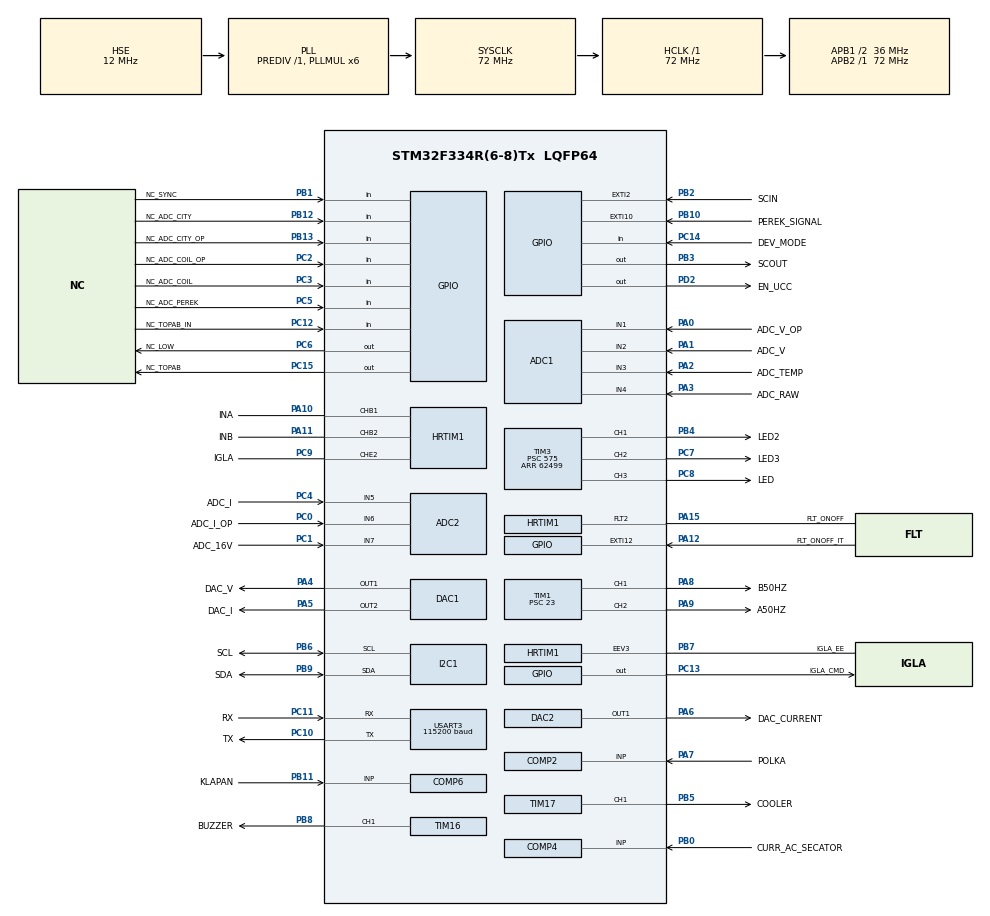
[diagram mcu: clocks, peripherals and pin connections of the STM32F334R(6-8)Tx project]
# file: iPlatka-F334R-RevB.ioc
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ADC1.AWD1HighThreshold=4095
ADC1.AWD1ITMode=ENABLE
ADC1.AWD1LowThreshold=1000
ADC1.AWD2HighThreshold=2000
ADC1.AWD2ITMode=ENABLE
ADC1.AWD2LowThreshold=1000
ADC1.AWD3HighThreshold=3000
ADC1.AWD3ITMode=ENABLE
ADC1.AWD3LowThreshold=2001
ADC1.AWDChannel-0\#ChannelRegularConversion=ADC_CHANNEL_3
ADC1.AWDChannel-6\#ChannelRegularConversion=ADC_CHANNEL_4
ADC1.Channel-0\#ChannelRegularConversion=ADC_CHANNEL_3
ADC1.Channel-6\#ChannelRegularConversion=ADC_CHANNEL_4
ADC1.ContinuousConvMode=ENABLE
ADC1.DMAContinuousRequests=ENABLE
ADC1.EOCSelection=ADC_EOC_SEQ_CONV
ADC1.EnableAnalogWatchDog1=true
ADC1.EnableAnalogWatchDog2=true
ADC1.EnableAnalogWatchDog3=true
ADC1.ExternalTrigInjecConv=ADC_EXTERNALTRIGINJECCONV_HRTIM_TRG2
ADC1.ExternalTrigInjecConvEdge=ADC_EXTERNALTRIGINJECCONV_EDGE_RISING
ADC1.InjNumberOfConversion=2
ADC1.InjectedChannel-1\#ChannelInjectedConversion=ADC_CHANNEL_2
ADC1.InjectedChannel-5\#ChannelInjectedConversion=ADC_CHANNEL_1
ADC1.InjectedOffset-1\#ChannelInjectedConversion=0
ADC1.InjectedOffset-5\#ChannelInjectedConversion=0
ADC1.InjectedOffsetNumber-1\#ChannelInjectedConversion=ADC_OFFSET_NONE
ADC1.InjectedOffsetNumber-5\#ChannelInjectedConversion=ADC_OFFSET_NONE
ADC1.InjectedRank-1\#ChannelInjectedConversion=1
ADC1.InjectedRank-5\#ChannelInjectedConversion=2
ADC1.InjectedSamplingTime-1\#ChannelInjectedConversion=ADC_SAMPLETIME_19CYCLES_5
ADC1.InjectedSamplingTime-5\#ChannelInjectedConversion=ADC_SAMPLETIME_19CYCLES_5
ADC1.MonitoredBy-0\#ChannelRegularConversion=ADC_ANALOGWATCHDOG_3
ADC1.MonitoredBy-6\#ChannelRegularConversion=ADC_ANALOGWATCHDOG_2
ADC1.NbrOfConversion=2
ADC1.NbrOfConversionFlag=1
ADC1.Offset-0\#ChannelRegularConversion=0
ADC1.Offset-6\#ChannelRegularConversion=0
ADC1.OffsetNumber-0\#ChannelRegularConversion=ADC_OFFSET_NONE
ADC1.OffsetNumber-6\#ChannelRegularConversion=ADC_OFFSET_NONE
ADC1.Rank-0\#ChannelRegularConversion=1
ADC1.Rank-6\#ChannelRegularConversion=2
ADC1.SamplingTime-0\#ChannelRegularConversion=ADC_SAMPLETIME_601CYCLES_5
ADC1.SamplingTime-6\#ChannelRegularConversion=ADC_SAMPLETIME_601CYCLES_5
ADC1.SubFamily=STM32F334x8
ADC1.WatchdogChannel=ADC_CHANNEL_4
ADC1.master=1
ADC2.AWD1HighThreshold=3000
ADC2.AWD1ITMode=ENABLE
ADC2.AWD1LowThreshold=1000
ADC2.AWD2HighThreshold=4000
ADC2.AWD2ITMode=ENABLE
ADC2.AWD2LowThreshold=1000
ADC2.AWD3HighThreshold=3000
ADC2.AWD3ITMode=ENABLE
ADC2.AWD3LowThreshold=1000
ADC2.AWDChannel-0\#ChannelRegularConversion=ADC_CHANNEL_7
ADC2.Channel-0\#ChannelRegularConversion=ADC_CHANNEL_7
ADC2.ContinuousConvMode=ENABLE
ADC2.DMAContinuousRequests=ENABLE
ADC2.EOCSelection=ADC_EOC_SEQ_CONV
ADC2.EnableAnalogWatchDog1=true
ADC2.EnableAnalogWatchDog2=true
ADC2.EnableAnalogWatchDog3=true
ADC2.ExternalTrigInjecConv=ADC_EXTERNALTRIGINJECCONV_HRTIM_TRG2
ADC2.InjAWDChannel-2\#ChannelInjectedConversion=ADC_CHANNEL_6
ADC2.InjMonitoredBy-2\#ChannelInjectedConversion=ADC_ANALOGWATCHDOG_2
ADC2.InjNumberOfConversion=2
ADC2.InjectedChannel-1\#ChannelInjectedConversion=ADC_CHANNEL_5
ADC2.InjectedChannel-2\#ChannelInjectedConversion=ADC_CHANNEL_6
ADC2.InjectedOffset-1\#ChannelInjectedConversion=0
ADC2.InjectedOffset-2\#ChannelInjectedConversion=0
ADC2.InjectedOffsetNumber-1\#ChannelInjectedConversion=ADC_OFFSET_NONE
ADC2.InjectedOffsetNumber-2\#ChannelInjectedConversion=ADC_OFFSET_NONE
ADC2.InjectedRank-1\#ChannelInjectedConversion=1
ADC2.InjectedRank-2\#ChannelInjectedConversion=2
ADC2.InjectedSamplingTime-1\#ChannelInjectedConversion=ADC_SAMPLETIME_19CYCLES_5
ADC2.InjectedSamplingTime-2\#ChannelInjectedConversion=ADC_SAMPLETIME_19CYCLES_5
ADC2.MonitoredBy-0\#ChannelRegularConversion=ADC_ANALOGWATCHDOG_3
ADC2.NbrOfConversionFlag=1
ADC2.Offset-0\#ChannelRegularConversion=0
ADC2.OffsetNumber-0\#ChannelRegularConversion=ADC_OFFSET_NONE
ADC2.Rank-0\#ChannelRegularConversion=1
ADC2.SamplingTime-0\#ChannelRegularConversion=ADC_SAMPLETIME_601CYCLES_5
ADC2.SubFamily=STM32F334x8
ADC2.WatchdogChannel=ADC_CHANNEL_7
COMP2.InvertingInput=COMP_INVERTINGINPUT_DAC1_CH2
COMP2.TriggerMode=COMP_TRIGGERMODE_NONE
COMP4.InvertingInput=COMP_INVERTINGINPUT_DAC2_CH1
COMP4.TriggerMode=COMP_TRIGGERMODE_NONE
COMP6.InvertingInput=COMP_INVERTINGINPUT_DAC1_CH2
COMP6.TriggerMode=COMP_TRIGGERMODE_IT_RISING_FALLING
DAC1.DAC_Trigger=DAC_TRIGGER_HRTIM1_DACTRG1
DAC1.DAC_Trigger2=DAC_TRIGGER_HRTIM1_DACTRG1
DAC1.TriangleAmplitude=DAC_TRIANGLEAMPLITUDE_7
DAC1.TriangleAmplitude2=DAC_TRIANGLEAMPLITUDE_7
DAC1.WaveGeneration=TriangleWaveGeneration
DAC1.WaveGeneration2=TriangleWaveGeneration
DAC2.DAC_Trigger=DAC_TRIGGER_HRTIM1_DACTRG3
Dma.ADC1.3.Direction=DMA_PERIPH_TO_MEMORY
Dma.ADC1.3.Instance=DMA1_Channel1
Dma.ADC1.3.MemDataAlignment=DMA_MDATAALIGN_HALFWORD
Dma.ADC1.3.MemInc=DMA_MINC_ENABLE
Dma.ADC1.3.Mode=DMA_CIRCULAR
Dma.ADC1.3.PeriphDataAlignment=DMA_PDATAALIGN_HALFWORD
Dma.ADC1.3.PeriphInc=DMA_PINC_DISABLE
Dma.ADC1.3.Priority=DMA_PRIORITY_HIGH
Dma.ADC2.4.Direction=DMA_PERIPH_TO_MEMORY
Dma.ADC2.4.Instance=DMA1_Channel4
Dma.ADC2.4.MemDataAlignment=DMA_MDATAALIGN_HALFWORD
Dma.ADC2.4.MemInc=DMA_MINC_ENABLE
Dma.ADC2.4.Mode=DMA_CIRCULAR
Dma.ADC2.4.PeriphDataAlignment=DMA_PDATAALIGN_HALFWORD
Dma.ADC2.4.PeriphInc=DMA_PINC_DISABLE
Dma.ADC2.4.Priority=DMA_PRIORITY_HIGH
Dma.I2C1_RX.5.Direction=DMA_PERIPH_TO_MEMORY
Dma.I2C1_RX.5.Instance=DMA1_Channel5
Dma.I2C1_RX.5.MemDataAlignment=DMA_MDATAALIGN_BYTE
Dma.I2C1_RX.5.MemInc=DMA_MINC_ENABLE
Dma.I2C1_RX.5.Mode=DMA_CIRCULAR
Dma.I2C1_RX.5.PeriphDataAlignment=DMA_PDATAALIGN_BYTE
Dma.I2C1_RX.5.PeriphInc=DMA_PINC_DISABLE
Dma.I2C1_RX.5.Priority=DMA_PRIORITY_LOW
Dma.I2C1_TX.2.Direction=DMA_MEMORY_TO_PERIPH
Dma.I2C1_TX.2.Instance=DMA1_Channel6
Dma.I2C1_TX.2.MemDataAlignment=DMA_MDATAALIGN_BYTE
Dma.I2C1_TX.2.MemInc=DMA_MINC_ENABLE
Dma.I2C1_TX.2.Mode=DMA_CIRCULAR
Dma.I2C1_TX.2.PeriphDataAlignment=DMA_PDATAALIGN_BYTE
Dma.I2C1_TX.2.PeriphInc=DMA_PINC_DISABLE
Dma.I2C1_TX.2.Priority=DMA_PRIORITY_MEDIUM
Dma.Request0=USART3_TX
Dma.Request1=USART3_RX
Dma.Request2=I2C1_TX
Dma.Request3=ADC1
Dma.Request4=ADC2
Dma.Request5=I2C1_RX
Dma.USART3_RX.1.Direction=DMA_PERIPH_TO_MEMORY
Dma.USART3_RX.1.Instance=DMA1_Channel3
Dma.USART3_RX.1.MemDataAlignment=DMA_MDATAALIGN_BYTE
Dma.USART3_RX.1.MemInc=DMA_MINC_ENABLE
Dma.USART3_RX.1.Mode=DMA_CIRCULAR
Dma.USART3_RX.1.PeriphDataAlignment=DMA_PDATAALIGN_BYTE
Dma.USART3_RX.1.PeriphInc=DMA_PINC_DISABLE
Dma.USART3_RX.1.Priority=DMA_PRIORITY_LOW
Dma.USART3_TX.0.Direction=DMA_MEMORY_TO_PERIPH
Dma.USART3_TX.0.Instance=DMA1_Channel2
Dma.USART3_TX.0.MemDataAlignment=DMA_MDATAALIGN_BYTE
Dma.USART3_TX.0.MemInc=DMA_MINC_ENABLE
Dma.USART3_TX.0.Mode=DMA_CIRCULAR
Dma.USART3_TX.0.PeriphDataAlignment=DMA_PDATAALIGN_BYTE
Dma.USART3_TX.0.PeriphInc=DMA_PINC_DISABLE
Dma.USART3_TX.0.Priority=DMA_PRIORITY_MEDIUM
FREERTOS.Tasks01=BootOcIgla,24,128,StartBootOcIgla,Default,NULL,Dynamic,NULL,NULL;BuzzerCoolerLed,16,128,StartBuzzerCoolerLed_5Sec,Default,NULL,Dynamic,NULL,NULL;ADC_TEMP_V16_RA,16,128,StartADC_TEMP_V16_RAW,Default,NULL,Dynamic,NULL,NULL;UART_I2C,8,128,StartUART_I2C,Default,NULL,Dynamic,NULL,NULL
FREERTOS.configTOTAL_HEAP_SIZE=2600
HRTIM1.ADCTrigger2_Source1=HRTIM_ADCTRIGGEREVENT24_MASTER_CMP2
HRTIM1.ADCTrigger2_Source2=HRTIM_ADCTRIGGEREVENT24_MASTER_CMP4
HRTIM1.ADCTrigger_Id2=HRTIM_ADCTRIGGER_2
HRTIM1.CaptureUnit1-No_output_TA=HRTIM_CAPTUREUNIT_1
HRTIM1.CaptureUnit1-No_output_TC=HRTIM_CAPTUREUNIT_1
HRTIM1.CaptureUnit1-No_output_TD=HRTIM_CAPTUREUNIT_1
HRTIM1.CaptureUnit2-No_output_TA=HRTIM_CAPTUREUNIT_2
HRTIM1.CaptureUnit2-No_output_TC=HRTIM_CAPTUREUNIT_2
HRTIM1.CompareUnit1-MasterTimer=HRTIM_COMPAREUNIT_1
HRTIM1.CompareUnit1-No_output_TA=__NULL
HRTIM1.CompareUnit1-Output_TB1TB2=HRTIM_COMPAREUNIT_1
HRTIM1.CompareUnit2-MasterTimer=HRTIM_COMPAREUNIT_2
HRTIM1.CompareUnit2-Output_TB1TB2=HRTIM_COMPAREUNIT_2
HRTIM1.CompareUnit3-MasterTimer=HRTIM_COMPAREUNIT_3
HRTIM1.CompareUnit3-Output_TB1TB2=HRTIM_COMPAREUNIT_3
HRTIM1.CompareUnit4-MasterTimer=HRTIM_COMPAREUNIT_4
HRTIM1.CompareUnit4-Output_TB1TB2=HRTIM_COMPAREUNIT_4
HRTIM1.CompareValue1-MasterTimer=3456
HRTIM1.CompareValue1-Output_TB1TB2=3456
HRTIM1.CompareValue2-MasterTimer=5760
HRTIM1.CompareValue2-Output_TB1TB2=32000
HRTIM1.CompareValue3-MasterTimer=35456
HRTIM1.CompareValue3-Output_TB1TB2=35456
HRTIM1.CompareValue4-MasterTimer=37760
HRTIM1.CompareValue4-Output_TB1TB2=64000
HRTIM1.DACSynchro-No_output_TA=HRTIM_DACSYNC_DACTRIGOUT_1
HRTIM1.DACSynchro-No_output_TC=HRTIM_DACSYNC_DACTRIGOUT_3
HRTIM1.DACSynchro-Output_TB1TB2=HRTIM_DACSYNC_NONE
HRTIM1.DACSynchro-Output_TE2=HRTIM_DACSYNC_DACTRIGOUT_1
HRTIM1.Event_EEV1=HRTIM_EVENT_1
HRTIM1.Event_EEV2=HRTIM_EVENT_2
HRTIM1.Event_EEV4=HRTIM_EVENT_4
HRTIM1.Event_EEV5=HRTIM_EVENT_5
HRTIM1.Event_EEV6=HRTIM_EVENT_6
HRTIM1.Event_EEV7=HRTIM_EVENT_7
HRTIM1.Event_EEV8=HRTIM_EVENT_8
HRTIM1.Event_EEV9=__NULL
HRTIM1.FastMode_EEV1=HRTIM_EVENTFASTMODE_ENABLE
HRTIM1.FastMode_EEV2=HRTIM_EVENTFASTMODE_ENABLE
HRTIM1.FastMode_EEV3=HRTIM_EVENTFASTMODE_ENABLE
HRTIM1.FastMode_EEV5=HRTIM_EVENTFASTMODE_ENABLE
HRTIM1.FaultEnable_Source1-No_output_TA=HRTIM_TIMFAULTENABLE_FAULT2
HRTIM1.FaultEnable_Source1-No_output_TC=HRTIM_TIMFAULTENABLE_FAULT2
HRTIM1.FaultEnable_Source1-No_output_TD=HRTIM_TIMFAULTENABLE_FAULT2
HRTIM1.FaultEnable_Source1-Output_TB1TB2=HRTIM_TIMFAULTENABLE_FAULT2
HRTIM1.FaultEnable_Source1-Output_TE2=HRTIM_TIMFAULTENABLE_FAULT2
HRTIM1.FaultLevel1-Output_TB1TB2=HRTIM_OUTPUTFAULTLEVEL_INACTIVE
HRTIM1.FaultLevel2-Output_TB1TB2=HRTIM_OUTPUTFAULTLEVEL_INACTIVE
HRTIM1.FaultLevel2-Output_TE2=HRTIM_OUTPUTFAULTLEVEL_INACTIVE
HRTIM1.Filter_EEV6=HRTIM_EVENTFILTER_15
HRTIM1.Filter_EEV8=HRTIM_EVENTFILTER_15
HRTIM1.Filter_FaultLine2=HRTIM_FAULTFILTER_15
HRTIM1.HRTIMInterruptResquests1=HRTIM_IT_FLT2
HRTIM1.HRTIMInterruptResquests2=HRTIM_IT_SYSFLT
HRTIM1.InterruptRequests1-No_output_TA=HRTIM_TIM_IT_CPT1
HRTIM1.InterruptRequests1-No_output_TC=HRTIM_TIM_IT_CPT1
HRTIM1.InterruptRequests1-No_output_TD=HRTIM_TIM_IT_CPT1
HRTIM1.InterruptRequests1_Master=HRTIM_MASTER_IT_MREP
HRTIM1.InterruptRequests2-No_output_TA=HRTIM_TIM_IT_CPT2
HRTIM1.InterruptRequests2-No_output_TC=HRTIM_TIM_IT_CPT2
HRTIM1.ModeTimeBase-No_output_TA=HRTIM_MODE_SINGLESHOT_RETRIGGERABLE
HRTIM1.ModeTimeBase-No_output_TC=HRTIM_MODE_SINGLESHOT_RETRIGGERABLE
HRTIM1.ModeTimeBase-No_output_TD=HRTIM_MODE_SINGLESHOT_RETRIGGERABLE
HRTIM1.ModeTimeBase-Output_TB1TB2=HRTIM_MODE_SINGLESHOT
HRTIM1.ModeTimeBase-Output_TE2=HRTIM_MODE_SINGLESHOT_RETRIGGERABLE
HRTIM1.NumberADCTriggerSource2=2
HRTIM1.NumberFaultEnable-No_output_TA=1
HRTIM1.NumberFaultEnable-No_output_TC=1
HRTIM1.NumberFaultEnable-No_output_TD=1
HRTIM1.NumberFaultEnable-Output_TB1TB2=1
HRTIM1.NumberFaultEnable-Output_TE2=1
HRTIM1.NumberInterruptRequests-No_output_TA=2
HRTIM1.NumberInterruptRequests-No_output_TC=2
HRTIM1.NumberInterruptRequests-No_output_TD=1
HRTIM1.NumberInterruptRequests_Master-MasterTimer=1
HRTIM1.NumberResetSource1-Output_TB1TB2=15
HRTIM1.NumberResetSource2-Output_TE2=8
HRTIM1.NumberResetSource2_TB=15
HRTIM1.NumberResetTrigger-No_output_TA=1
HRTIM1.NumberResetTrigger-No_output_TC=1
HRTIM1.NumberResetTrigger-No_output_TD=1
HRTIM1.NumberResetTrigger-Output_TB1TB2=1
HRTIM1.NumberResetTrigger-Output_TE2=1
HRTIM1.NumberSetSource1-Output_TB1TB2=1
HRTIM1.NumberSetSource2-Output_TE2=1
HRTIM1.NumberSetSource2_TB=1
HRTIM1.NumberTriggerSource_Captureconfig1-No_output_TA=1
HRTIM1.NumberTriggerSource_Captureconfig1-No_output_TC=1
HRTIM1.NumberTriggerSource_Captureconfig1-No_output_TD=1
HRTIM1.NumberTriggerSource_Captureconfig2-No_output_TA=1
HRTIM1.NumberTriggerSource_Captureconfig2-No_output_TC=1
HRTIM1.NumberUpdateTrigger-No_output_TA=1
HRTIM1.NumberUpdateTrigger-No_output_TC=1
HRTIM1.NumberUpdateTrigger-No_output_TD=1
HRTIM1.NumberUpdateTrigger-Output_TB1TB2=1
HRTIM1.NumberUpdateTrigger-Output_TE2=1
HRTIM1.Periode_MASTER=64000
HRTIM1.Periode_TA=32000
HRTIM1.Periode_TB=64000
HRTIM1.Periode_TC=32000
HRTIM1.Periode_TD=64000
HRTIM1.Periode_TE=64000
HRTIM1.Polarity_FaultLine2=HRTIM_FAULTPOLARITY_LOW
HRTIM1.PreloadEnable-MasterTimer=HRTIM_PRELOAD_ENABLED
HRTIM1.PreloadEnable-Output_TE2=HRTIM_PRELOAD_DISABLED
HRTIM1.PrescalerRatio_MASTER=HRTIM_PRESCALERRATIO_MUL16
HRTIM1.PrescalerRatio_TA=HRTIM_PRESCALERRATIO_MUL16
HRTIM1.PrescalerRatio_TB=HRTIM_PRESCALERRATIO_MUL16
HRTIM1.PrescalerRatio_TC=HRTIM_PRESCALERRATIO_MUL16
HRTIM1.PrescalerRatio_TD=HRTIM_PRESCALERRATIO_MUL16
HRTIM1.PrescalerRatio_TE=HRTIM_PRESCALERRATIO_MUL16
HRTIM1.RepetitionCounter-MasterTimer=0
HRTIM1.RepetitionUpdate-MasterTimer=HRTIM_UPDATEONREPETITION_ENABLED
HRTIM1.RepetitionUpdate-No_output_TA=HRTIM_UPDATEONREPETITION_ENABLED
HRTIM1.RepetitionUpdate-No_output_TC=HRTIM_UPDATEONREPETITION_ENABLED
HRTIM1.RepetitionUpdate-No_output_TD=HRTIM_UPDATEONREPETITION_ENABLED
HRTIM1.RepetitionUpdate-Output_TB1TB2=HRTIM_UPDATEONREPETITION_ENABLED
HRTIM1.RepetitionUpdate-Output_TE2=HRTIM_UPDATEONREPETITION_ENABLED
HRTIM1.ResetOutput1_Source1-Output_TB1TB2=HRTIM_OUTPUTRESET_TIMCMP2
HRTIM1.ResetOutput1_Source10-Output_TB1TB2=HRTIM_OUTPUTRESET_EEV_4
HRTIM1.ResetOutput1_Source11-Output_TB1TB2=HRTIM_OUTPUTRESET_EEV_5
HRTIM1.ResetOutput1_Source12-Output_TB1TB2=HRTIM_OUTPUTRESET_EEV_6
HRTIM1.ResetOutput1_Source13-Output_TB1TB2=HRTIM_OUTPUTRESET_EEV_7
HRTIM1.ResetOutput1_Source14-Output_TB1TB2=HRTIM_OUTPUTRESET_EEV_8
HRTIM1.ResetOutput1_Source15-Output_TB1TB2=HRTIM_OUTPUTRESET_EEV_1
HRTIM1.ResetOutput1_Source2-Output_TB1TB2=HRTIM_OUTPUTRESET_TIMCMP3
HRTIM1.ResetOutput1_Source3-Output_TB1TB2=HRTIM_OUTPUTRESET_TIMCMP4
HRTIM1.ResetOutput1_Source4-Output_TB1TB2=HRTIM_OUTPUTRESET_TIMPER
HRTIM1.ResetOutput1_Source5-Output_TB1TB2=HRTIM_OUTPUTRESET_UPDATE
HRTIM1.ResetOutput1_Source6-Output_TB1TB2=HRTIM_OUTPUTRESET_MASTERPER
HRTIM1.ResetOutput1_Source7-Output_TB1TB2=HRTIM_OUTPUTRESET_MASTERCMP3
HRTIM1.ResetOutput1_Source8-Output_TB1TB2=HRTIM_OUTPUTRESET_MASTERCMP4
HRTIM1.ResetOutput1_Source9-Output_TB1TB2=HRTIM_OUTPUTRESET_EEV_2
HRTIM1.ResetOutput2_Source1-Output_TB1TB2=HRTIM_OUTPUTRESET_TIMCMP1
HRTIM1.ResetOutput2_Source1-Output_TE2=HRTIM_OUTPUTRESET_EEV_3
HRTIM1.ResetOutput2_Source10-Output_TB1TB2=HRTIM_OUTPUTRESET_EEV_4
HRTIM1.ResetOutput2_Source11-Output_TB1TB2=HRTIM_OUTPUTRESET_EEV_5
HRTIM1.ResetOutput2_Source12-Output_TB1TB2=HRTIM_OUTPUTRESET_EEV_6
HRTIM1.ResetOutput2_Source13-Output_TB1TB2=HRTIM_OUTPUTRESET_EEV_8
HRTIM1.ResetOutput2_Source14-Output_TB1TB2=HRTIM_OUTPUTRESET_EEV_7
HRTIM1.ResetOutput2_Source15-Output_TB1TB2=HRTIM_OUTPUTRESET_EEV_1
HRTIM1.ResetOutput2_Source2-Output_TB1TB2=HRTIM_OUTPUTRESET_TIMCMP2
HRTIM1.ResetOutput2_Source2-Output_TE2=HRTIM_OUTPUTRESET_EEV_4
HRTIM1.ResetOutput2_Source3-Output_TB1TB2=HRTIM_OUTPUTRESET_TIMCMP4
HRTIM1.ResetOutput2_Source3-Output_TE2=HRTIM_OUTPUTRESET_EEV_6
HRTIM1.ResetOutput2_Source4-Output_TB1TB2=HRTIM_OUTPUTRESET_UPDATE
HRTIM1.ResetOutput2_Source4-Output_TE2=HRTIM_OUTPUTRESET_EEV_5
HRTIM1.ResetOutput2_Source5-Output_TB1TB2=HRTIM_OUTPUTRESET_TIMPER
HRTIM1.ResetOutput2_Source5-Output_TE2=HRTIM_OUTPUTRESET_EEV_2
HRTIM1.ResetOutput2_Source6-Output_TB1TB2=HRTIM_OUTPUTRESET_MASTERCMP1
HRTIM1.ResetOutput2_Source6-Output_TE2=HRTIM_OUTPUTRESET_EEV_8
HRTIM1.ResetOutput2_Source7-Output_TB1TB2=HRTIM_OUTPUTRESET_MASTERCMP2
HRTIM1.ResetOutput2_Source7-Output_TE2=HRTIM_OUTPUTRESET_EEV_7
HRTIM1.ResetOutput2_Source8-Output_TB1TB2=HRTIM_OUTPUTRESET_MASTERPER
HRTIM1.ResetOutput2_Source8-Output_TE2=HRTIM_OUTPUTRESET_EEV_1
HRTIM1.ResetOutput2_Source9-Output_TB1TB2=HRTIM_OUTPUTRESET_EEV_2
HRTIM1.ResetTrigger1-No_output_TA=HRTIM_TIMRESETTRIGGER_MASTER_PER
HRTIM1.ResetTrigger1-No_output_TC=HRTIM_TIMRESETTRIGGER_OTHER2_CMP2
HRTIM1.ResetTrigger1-No_output_TD=HRTIM_TIMRESETTRIGGER_MASTER_PER
HRTIM1.ResetTrigger1-Output_TB1TB2=HRTIM_TIMRESETTRIGGER_MASTER_PER
HRTIM1.ResetTrigger1-Output_TE2=HRTIM_TIMRESETTRIGGER_MASTER_PER
HRTIM1.ResetUpdate-No_output_TA=HRTIM_TIMUPDATEONRESET_ENABLED
HRTIM1.ResetUpdate-No_output_TC=HRTIM_TIMUPDATEONRESET_ENABLED
HRTIM1.ResetUpdate-No_output_TD=HRTIM_TIMUPDATEONRESET_ENABLED
HRTIM1.ResetUpdate-Output_TB1TB2=HRTIM_TIMUPDATEONRESET_ENABLED
HRTIM1.ResetUpdate-Output_TE2=HRTIM_TIMUPDATEONRESET_ENABLED
HRTIM1.SetOutput1_Source1-Output_TB1TB2=HRTIM_OUTPUTSET_TIMCMP1
HRTIM1.SetOutput2_Source1-Output_TB1TB2=HRTIM_OUTPUTSET_TIMCMP3
HRTIM1.SetOutput2_Source1-Output_TE2=HRTIM_OUTPUTSET_EEV_3
HRTIM1.Source_EEV2=HRTIM_EVENTSRC_4
HRTIM1.Source_EEV4=HRTIM_EVENTSRC_4
HRTIM1.Source_EEV6=HRTIM_EVENTSRC_4
HRTIM1.TriggerCapture1_Source1-No_output_TA=HRTIM_CAPTURETRIGGER_EEV_1
HRTIM1.TriggerCapture1_Source1-No_output_TC=HRTIM_CAPTURETRIGGER_EEV_1
HRTIM1.TriggerCapture1_Source1-No_output_TD=HRTIM_CAPTURETRIGGER_EEV_8
HRTIM1.TriggerCapture2_Source1-No_output_TA=HRTIM_CAPTURETRIGGER_EEV_7
HRTIM1.TriggerCapture2_Source1-No_output_TC=HRTIM_CAPTURETRIGGER_EEV_7
HRTIM1.UpdateTrigger1-No_output_TA=HRTIM_TIMUPDATETRIGGER_MASTER
HRTIM1.UpdateTrigger1-No_output_TC=HRTIM_TIMUPDATETRIGGER_MASTER
HRTIM1.UpdateTrigger1-No_output_TD=HRTIM_TIMUPDATETRIGGER_MASTER
HRTIM1.UpdateTrigger1-Output_TB1TB2=HRTIM_TIMUPDATETRIGGER_MASTER
HRTIM1.UpdateTrigger1-Output_TE2=HRTIM_TIMUPDATETRIGGER_MASTER
IWDG.Prescaler=IWDG_PRESCALER_256
Mcu.Family=STM32F3
Mcu.Name=STM32F334R(6-8)Tx
Mcu.Package=LQFP64
NVIC.ADC1_2_IRQn=true\:2\:0\:true\:false\:true\:false\:true\:true
NVIC.COMP4_6_IRQn=true\:1\:0\:true\:false\:true\:false\:false\:true
NVIC.DMA1_Channel1_IRQn=true\:1\:0\:true\:false\:true\:false\:false\:true
NVIC.DMA1_Channel2_IRQn=true\:5\:0\:false\:false\:true\:true\:false\:true
NVIC.DMA1_Channel3_IRQn=true\:5\:0\:false\:false\:true\:true\:false\:true
NVIC.DMA1_Channel4_IRQn=true\:4\:0\:true\:false\:true\:false\:false\:true
NVIC.DMA1_Channel5_IRQn=true\:5\:0\:false\:false\:true\:true\:false\:true
NVIC.DMA1_Channel6_IRQn=true\:5\:0\:false\:false\:true\:true\:false\:true
NVIC.EXTI15_10_IRQn=true\:4\:0\:true\:false\:true\:false\:true\:true
NVIC.EXTI2_TSC_IRQn=true\:4\:0\:true\:false\:true\:false\:true\:true
NVIC.HRTIM1_FLT_IRQn=true\:0\:0\:true\:false\:true\:false\:true\:true
NVIC.HRTIM1_Master_IRQn=true\:0\:0\:true\:false\:true\:false\:true\:true
NVIC.HRTIM1_TIMA_IRQn=true\:0\:0\:false\:false\:true\:false\:true\:true
NVIC.HRTIM1_TIMC_IRQn=true\:0\:0\:false\:false\:true\:false\:true\:true
NVIC.HRTIM1_TIMD_IRQn=true\:0\:0\:false\:false\:true\:false\:true\:true
NVIC.PVD_IRQn=true\:4\:0\:true\:false\:true\:false\:true\:true
NVIC.PriorityGroup=NVIC_PRIORITYGROUP_4
NVIC.TIM1_UP_TIM16_IRQn=true\:1\:0\:true\:false\:true\:false\:true\:true
PA0.GPIO_Label=ADC_V_OP
PA0.Mode=IN1-Single-Ended
PA0.Signal=ADC1_IN1
PA1.GPIO_Label=ADC_V
PA1.Mode=IN2-Single-Ended
PA1.Signal=ADC1_IN2
PA10.GPIO_Label=INA
PA10.Mode=Output_TB1TB2
PA10.Signal=HRTIM1_CHB1
PA11.GPIO_Label=INB
PA11.Mode=Output_TB1TB2
PA11.Signal=HRTIM1_CHB2
PA12.GPIO_Label=FLT_ONOFF_IT
PA12.Signal=GPXTI12
PA13.GPIO_Label=DIO
PA13.Mode=Serial_Wire
PA13.Signal=SYS_JTMS-SWDIO
PA14.GPIO_Label=CLK
PA14.Mode=Serial_Wire
PA14.Signal=SYS_JTCK-SWCLK
PA15.GPIO_Label=FLT_ONOFF
PA15.Mode=Fault_Enable2
PA15.Signal=HRTIM1_FLT2
PA2.GPIO_Label=ADC_TEMP
PA2.Mode=IN3-Single-Ended
PA2.Signal=ADC1_IN3
PA3.GPIO_Label=ADC_RAW
PA3.Mode=IN4-Single-Ended
PA3.Signal=ADC1_IN4
PA4.GPIO_Label=DAC_V
PA4.Signal=COMP_DAC11_group
PA5.GPIO_Label=DAC_I
PA5.Signal=COMP_DAC12_group
PA6.GPIO_Label=DAC_CURRENT
PA6.Signal=COMP_DAC21_group
PA7.GPIO_Label=POLKA
PA7.Mode=INP
PA7.Signal=COMP2_INP
PA8.GPIO_Label=B50HZ
PA8.Signal=S_TIM1_CH1
PA9.GPIO_Label=A50HZ
PA9.Signal=S_TIM1_CH2
PB0.GPIO_Label=CURR_AC_SECATOR
PB0.Signal=SharedAnalog_PB0
PB1.GPIO_Label=NC_SYNC
PB1.Signal=GPIO_Input
PB10.GPIO_Label=PEREK_SIGNAL
PB10.GPIO_ModeDefaultEXTI=GPIO_MODE_IT_RISING_FALLING
PB10.Signal=GPXTI10
PB11.GPIO_Label=KLAPAN
PB11.Mode=INP
PB11.Signal=COMP6_INP
PB12.GPIO_Label=NC_ADC_CITY
PB12.Signal=GPIO_Input
PB13.GPIO_Label=NC_ADC_CITY_OP
PB13.Signal=GPIO_Input
PB2.GPIO_Label=SCIN
PB2.GPIO_ModeDefaultEXTI=GPIO_MODE_IT_RISING_FALLING
PB2.Signal=GPXTI2
PB3.GPIO_Label=SCOUT
PB3.GPIO_Speed=GPIO_SPEED_FREQ_HIGH
PB3.Signal=GPIO_Output
PB4.GPIO_Label=LED2
PB4.Signal=S_TIM3_CH1
PB5.GPIO_Label=COOLER
PB5.Signal=S_TIM17_CH1
PB6.GPIO_Label=SCL
PB6.Mode=I2C
PB6.Signal=I2C1_SCL
PB7.GPIO_Label=IGLA_EE
PB7.Mode=External_Evt_enable13
PB7.Signal=HRTIM1_EEV3
PB8.GPIO_Label=BUZZER
PB8.Signal=S_TIM16_CH1
PB9.GPIO_Label=SDA
PB9.Mode=I2C
PB9.Signal=I2C1_SDA
PC0.GPIO_Label=ADC_I_OP
PC0.Signal=ADCx_IN6
PC1.GPIO_Label=ADC_16V
PC1.Signal=ADCx_IN7
PC10.GPIO_Label=TX
PC10.Mode=Asynchronous
PC10.Signal=USART3_TX
PC11.GPIO_Label=RX
PC11.Mode=Asynchronous
PC11.Signal=USART3_RX
PC12.GPIO_Label=NC_TOPAB_IN
PC12.Signal=GPIO_Input
PC13.GPIO_Label=IGLA_CMD
PC13.Signal=GPIO_Output
PC14\ /\ OSC32_IN.GPIO_Label=DEV_MODE
PC14\ /\ OSC32_IN.Signal=GPIO_Input
PC15\ /\ OSC32_OUT.GPIO_Label=NC_TOPAB
PC15\ /\ OSC32_OUT.Signal=GPIO_Output
PC2.GPIO_Label=NC_ADC_COIL_OP
PC2.Signal=GPIO_Input
PC3.GPIO_Label=NC_ADC_COIL
PC3.Signal=GPIO_Input
PC4.GPIO_Label=ADC_I
PC4.Mode=IN5-Single-Ended
PC4.Signal=ADC2_IN5
PC5.GPIO_Label=NC_ADC_PEREK
PC5.Signal=GPIO_Input
PC6.GPIO_Label=NC_LOW
PC6.GPIO_Speed=GPIO_SPEED_FREQ_HIGH
PC6.Signal=GPIO_Output
PC7.GPIO_Label=LED3
PC7.Signal=S_TIM3_CH2
PC8.GPIO_Label=LED
PC8.Signal=S_TIM3_CH3
PC9.GPIO_Label=IGLA
PC9.Mode=Output_TE2
PC9.Signal=HRTIM1_CHE2
PD2.GPIO_Label=EN_UCC
PD2.GPIO_Speed=GPIO_SPEED_FREQ_HIGH
PD2.Signal=GPIO_Output
PF0\ /\ OSC_IN.GPIO_Label=OSC_IN
PF0\ /\ OSC_IN.Mode=HSE-External-Oscillator
PF0\ /\ OSC_IN.Signal=RCC_OSC_IN
PF1\ /\ OSC_OUT.GPIO_Label=OSC_OUT
PF1\ /\ OSC_OUT.Mode=HSE-External-Oscillator
PF1\ /\ OSC_OUT.Signal=RCC_OSC_OUT
ProjectManager.HeapSize=0x200
ProjectManager.StackSize=0x400
ProjectManager.TargetToolchain=STM32CubeIDE
RCC.AHBFreq_Value=72000000
RCC.APB1CLKDivider=RCC_HCLK_DIV2
RCC.APB1Freq_Value=36000000
RCC.APB1TimFreq_Value=72000000
RCC.APB2Freq_Value=72000000
RCC.APB2TimFreq_Value=72000000
RCC.CortexFreq_Value=72000000
RCC.HCLKFreq_Value=72000000
RCC.HRTIMSelection=RCC_HRTIM1CLK_PLLCLK
RCC.HSE_VALUE=12000000
RCC.HSI_VALUE=8000000
RCC.LSE_VALUE=32768
RCC.PLLMUL=RCC_PLL_MUL6
RCC.PLLSourceVirtual=RCC_PLLSOURCE_HSE
RCC.SYSCLKFreq_VALUE=72000000
RCC.SYSCLKSourceVirtual=RCC_SYSCLKSOURCE_PLLCLK
RCC.TIM1Selection=RCC_TIM1CLK_PLLCLK
SH.ADCx_IN6.0=ADC2_IN6,IN6-Single-Ended
SH.ADCx_IN7.0=ADC2_IN7,IN7-Single-Ended
SH.COMP_DAC11_group.0=DAC1_OUT1,DAC_OUT1
SH.COMP_DAC12_group.0=DAC1_OUT2,DAC_OUT2
SH.COMP_DAC21_group.0=DAC2_OUT1,Switch_Enable_OUT1
SH.S_TIM16_CH1.0=TIM16_CH1,PWM Generation1 CH1
SH.S_TIM17_CH1.0=TIM17_CH1,PWM Generation1 CH1
SH.S_TIM1_CH1.0=TIM1_CH1,PWM Generation1 CH1
SH.S_TIM1_CH2.0=TIM1_CH2,PWM Generation2 CH2
SH.S_TIM3_CH1.0=TIM3_CH1,PWM Generation1 CH1
SH.S_TIM3_CH2.0=TIM3_CH2,PWM Generation2 CH2
SH.S_TIM3_CH3.0=TIM3_CH3,PWM Generation3 CH3
SH.SharedAnalog_PB0.0=ADC1_IN11
SH.SharedAnalog_PB0.1=COMP4_INP,INP
TIM1.AutoReloadPreload=TIM_AUTORELOAD_PRELOAD_ENABLE
TIM1.Channel-PWM\ Generation1\ CH1=TIM_CHANNEL_1
TIM1.Channel-PWM\ Generation2\ CH2=TIM_CHANNEL_2
TIM1.ClockDivision=TIM_CLOCKDIVISION_DIV1
TIM1.OCFastMode_PWM-PWM\ Generation1\ CH1=TIM_OCFAST_ENABLE
TIM1.OCFastMode_PWM-PWM\ Generation2\ CH2=TIM_OCFAST_ENABLE
TIM1.OCIdleState_1=TIM_OCIDLESTATE_RESET
TIM1.OCIdleState_2=TIM_OCIDLESTATE_RESET
TIM1.OCMode_PWM-PWM\ Generation2\ CH2=TIM_OCMODE_PWM2
TIM1.OCPolarity_1=TIM_OCPOLARITY_HIGH
TIM1.OCPolarity_2=TIM_OCPOLARITY_HIGH
TIM1.Period=59999
TIM1.Prescaler=23
TIM1.Pulse-PWM\ Generation1\ CH1=29700
TIM1.Pulse-PWM\ Generation2\ CH2=30300
TIM16.AutoReloadPreload=TIM_AUTORELOAD_PRELOAD_ENABLE
TIM16.Channel=TIM_CHANNEL_1
TIM16.ClockDivision=TIM_CLOCKDIVISION_DIV4
TIM16.OCFastMode_PWM=TIM_OCFAST_ENABLE
TIM16.Period=62499
TIM17.AutoReloadPreload=TIM_AUTORELOAD_PRELOAD_ENABLE
TIM17.Channel=TIM_CHANNEL_1
TIM17.ClockDivision=TIM_CLOCKDIVISION_DIV4
TIM17.OCFastMode_PWM=TIM_OCFAST_ENABLE
TIM17.Period=35999
TIM17.Prescaler=0
TIM17.RepetitionCounter=0
TIM3.AutoReloadPreload=TIM_AUTORELOAD_PRELOAD_ENABLE
TIM3.Channel-PWM\ Generation1\ CH1=TIM_CHANNEL_1
TIM3.Channel-PWM\ Generation2\ CH2=TIM_CHANNEL_2
TIM3.Channel-PWM\ Generation3\ CH3=TIM_CHANNEL_3
TIM3.ClockDivision=TIM_CLOCKDIVISION_DIV1
TIM3.OCFastMode_PWM-PWM\ Generation1\ CH1=TIM_OCFAST_ENABLE
TIM3.OCFastMode_PWM-PWM\ Generation2\ CH2=TIM_OCFAST_ENABLE
TIM3.OCFastMode_PWM-PWM\ Generation3\ CH3=TIM_OCFAST_ENABLE
TIM3.Period=62499
TIM3.Prescaler=575
USART3.BaudRate=115200
USART3.VirtualMode-Asynchronous=VM_ASYNC
VP_COMP2_VS_DAC1OUT2.Mode=INM_DAC1OUT2
VP_COMP4_VS_DAC2OUT1.Mode=INM_DAC2OUT1
VP_COMP6_VS_DAC1OUT2.Mode=INM_DAC1OUT2
VP_CRC_VS_CRC.Mode=CRC_Activate
VP_FREERTOS_VS_CMSIS_V2.Mode=CMSIS_V2
VP_HRTIM1_VS_hrtimMasterTimerNoOutput.Mode=MasterTimer
VP_HRTIM1_VS_hrtimTimerANoOutput.Mode=No_output_TA
VP_HRTIM1_VS_hrtimTimerCNoOutput.Mode=No_output_TC
VP_HRTIM1_VS_hrtimTimerDNoOutput.Mode=No_output_TD
VP_IWDG_VS_IWDG.Mode=IWDG_Activate
VP_RTC_VS_RTC_Activate.Mode=RTC_Enabled
VP_RTC_VS_RTC_Calendar.Mode=RTC_Calendar
VP_TIM16_VS_ClockSourceINT.Mode=Enable_Timer
VP_TIM17_VS_ClockSourceINT.Mode=Enable_Timer
VP_TIM1_VS_ClockSourceINT.Mode=Internal
VP_TIM1_VS_OPM.Mode=OPM_bit
VP_TIM3_VS_ClockSourceINT.Mode=Internal
board=custom

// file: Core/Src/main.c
/* USER CODE BEGIN Header */
/**
  ******************************************************************************
  * @file           : main.c
  * @brief          : Main program body
  ******************************************************************************
  * @attention
  *
  * <h2><center>&copy; Copyright (c) 2020 STMicroelectronics.
  * All rights reserved.</center></h2>
  *
  * This software component is licensed by ST under BSD 3-Clause license,
  * the "License"; You may not use this file except in compliance with the
  * License. You may obtain a copy of the License at:
  *                        opensource.org/licenses/BSD-3-Clause
  *
  ******************************************************************************
  */
/* USER CODE END Header */

#include "main.h"
#include "cmsis_os.h"
#include "adc.h"
#include "comp.h"
#include "crc.h"
#include "dac.h"
#include "dma.h"
#include "hrtim.h"
#include "i2c.h"
#include "iwdg.h"
#include "rtc.h"
#include "tim.h"
#include "usart.h"
#include "gpio.h"

void SystemClock_Config(void);
void MX_FREERTOS_Init(void);

/* USER CODE BEGIN 0 */
void HAL_TIM_PeriodElapsedCallback(TIM_HandleTypeDef *htim)
{
        if(htim->Instance == TIM1) //check if the interrupt comes from TIM1
        {
        	HAL_TIM_PWM_Start(&htim1, TIM_CHANNEL_1);
            HAL_TIM_PWM_Start(&htim1, TIM_CHANNEL_2);
        }
}
/* USER CODE END 0 */

int main(void)
{

  /* MCU Configuration--------------------------------------------------------*/

  /* Reset of all peripherals, Initializes the Flash interface and the Systick. */
  HAL_Init();

  /* Configure the system clock */
  SystemClock_Config();

  /* Initialize all configured peripherals */
  MX_GPIO_Init();
  MX_DMA_Init();
  MX_ADC1_Init();
  MX_ADC2_Init();
  MX_COMP2_Init();
  MX_COMP4_Init();
  MX_COMP6_Init();
  MX_CRC_Init();
  MX_DAC1_Init();
  MX_DAC2_Init();
  MX_HRTIM1_Init();
  MX_I2C1_Init();
  MX_IWDG_Init();
  MX_RTC_Init();
  MX_TIM1_Init();
  MX_TIM3_Init();
  MX_TIM16_Init();
  MX_TIM17_Init();
  MX_USART3_UART_Init();

  /* Init scheduler */
  osKernelInitialize();  /* Call init function for freertos objects (in freertos.c) */
  MX_FREERTOS_Init();
  /* Start scheduler */
  osKernelStart();

  /* We should never get here as control is now taken by the scheduler */
  /* Infinite loop */
  while (1)
  {

  }
}

void SystemClock_Config(void)
{
  RCC_OscInitTypeDef RCC_OscInitStruct = {0};
  RCC_ClkInitTypeDef RCC_ClkInitStruct = {0};
  RCC_PeriphCLKInitTypeDef PeriphClkInit = {0};

  /** Initializes the CPU, AHB and APB busses clocks
  */
  RCC_OscInitStruct.OscillatorType = RCC_OSCILLATORTYPE_HSI|RCC_OSCILLATORTYPE_LSI
                              |RCC_OSCILLATORTYPE_HSE;
  RCC_OscInitStruct.HSEState = RCC_HSE_ON;
  RCC_OscInitStruct.HSEPredivValue = RCC_HSE_PREDIV_DIV1;
  RCC_OscInitStruct.HSIState = RCC_HSI_ON;
  RCC_OscInitStruct.HSICalibrationValue = RCC_HSICALIBRATION_DEFAULT;
  RCC_OscInitStruct.LSIState = RCC_LSI_ON;
  RCC_OscInitStruct.PLL.PLLState = RCC_PLL_ON;
  RCC_OscInitStruct.PLL.PLLSource = RCC_PLLSOURCE_HSE;
  RCC_OscInitStruct.PLL.PLLMUL = RCC_PLL_MUL6;
  if (HAL_RCC_OscConfig(&RCC_OscInitStruct) != HAL_OK)
  {
    Error_Handler();
  }
  /** Initializes the CPU, AHB and APB busses clocks
  */
  RCC_ClkInitStruct.ClockType = RCC_CLOCKTYPE_HCLK|RCC_CLOCKTYPE_SYSCLK
                              |RCC_CLOCKTYPE_PCLK1|RCC_CLOCKTYPE_PCLK2;
  RCC_ClkInitStruct.SYSCLKSource = RCC_SYSCLKSOURCE_PLLCLK;
  RCC_ClkInitStruct.AHBCLKDivider = RCC_SYSCLK_DIV1;
  RCC_ClkInitStruct.APB1CLKDivider = RCC_HCLK_DIV2;
  RCC_ClkInitStruct.APB2CLKDivider = RCC_HCLK_DIV1;

  if (HAL_RCC_ClockConfig(&RCC_ClkInitStruct, FLASH_LATENCY_2) != HAL_OK)
  {
    Error_Handler();
  }
  PeriphClkInit.PeriphClockSelection = RCC_PERIPHCLK_HRTIM1|RCC_PERIPHCLK_I2C1
                              |RCC_PERIPHCLK_RTC|RCC_PERIPHCLK_TIM1
                              |RCC_PERIPHCLK_ADC12;
  PeriphClkInit.Adc12ClockSelection = RCC_ADC12PLLCLK_DIV1;
  PeriphClkInit.I2c1ClockSelection = RCC_I2C1CLKSOURCE_HSI;
  PeriphClkInit.RTCClockSelection = RCC_RTCCLKSOURCE_LSI;
  PeriphClkInit.Tim1ClockSelection = RCC_TIM1CLK_PLLCLK;
  PeriphClkInit.Hrtim1ClockSelection = RCC_HRTIM1CLK_PLLCLK;
  if (HAL_RCCEx_PeriphCLKConfig(&PeriphClkInit) != HAL_OK)
  {
    Error_Handler();
  }
}

void Error_Handler(void)
{
}

/************************ (C) COPYRIGHT STMicroelectronics *****END OF FILE****/

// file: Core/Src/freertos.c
/* USER CODE BEGIN Header */
/**
  ******************************************************************************
  * File Name          : freertos.c
  * Description        : Code for freertos applications
  ******************************************************************************
  * @attention
  *
  * <h2><center>&copy; Copyright (c) 2020 STMicroelectronics.
  * All rights reserved.</center></h2>
  *
  * This software component is licensed by ST under Ultimate Liberty license
  * SLA0044, the "License"; You may not use this file except in compliance with
  * the License. You may obtain a copy of the License at:
  *                             www.st.com/SLA0044
  *
  ******************************************************************************
  */
/* USER CODE END Header */

#include "FreeRTOS.h"
#include "task.h"
#include "main.h"
#include "cmsis_os.h"

/* USER CODE BEGIN Includes */
#include "tim.h"
/* USER CODE END Includes */

/* Definitions for BootOcIgla */
osThreadId_t BootOcIglaHandle;
const osThreadAttr_t BootOcIgla_attributes = {
  .name = "BootOcIgla",
  .priority = (osPriority_t) osPriorityNormal,
  .stack_size = 128 * 4
};
/* Definitions for BuzzerCoolerLed */
osThreadId_t BuzzerCoolerLedHandle;
const osThreadAttr_t BuzzerCoolerLed_attributes = {
  .name = "BuzzerCoolerLed",
  .priority = (osPriority_t) osPriorityBelowNormal,
  .stack_size = 128 * 4
};
/* Definitions for ADC_TEMP_V16_RA */
osThreadId_t ADC_TEMP_V16_RAHandle;
const osThreadAttr_t ADC_TEMP_V16_RA_attributes = {
  .name = "ADC_TEMP_V16_RA",
  .priority = (osPriority_t) osPriorityBelowNormal,
  .stack_size = 128 * 4
};
/* Definitions for UART_I2C */
osThreadId_t UART_I2CHandle;
const osThreadAttr_t UART_I2C_attributes = {
  .name = "UART_I2C",
  .priority = (osPriority_t) osPriorityLow,
  .stack_size = 128 * 4
};

void StartBootOcIgla(void *argument);
void StartBuzzerCoolerLed_5Sec(void *argument);
void StartADC_TEMP_V16_RAW(void *argument);
void StartUART_I2C(void *argument);

void MX_FREERTOS_Init(void); /* (MISRA C 2004 rule 8.1) */

void MX_FREERTOS_Init(void) {

  /* Create the thread(s) */
  /* creation of BootOcIgla */
  BootOcIglaHandle = osThreadNew(StartBootOcIgla, NULL, &BootOcIgla_attributes);

  /* creation of BuzzerCoolerLed */
  BuzzerCoolerLedHandle = osThreadNew(StartBuzzerCoolerLed_5Sec, NULL, &BuzzerCoolerLed_attributes);

  /* creation of ADC_TEMP_V16_RA */
  ADC_TEMP_V16_RAHandle = osThreadNew(StartADC_TEMP_V16_RAW, NULL, &ADC_TEMP_V16_RA_attributes);

  /* creation of UART_I2C */
  UART_I2CHandle = osThreadNew(StartUART_I2C, NULL, &UART_I2C_attributes);

}

void StartBootOcIgla(void *argument)
{
  /* USER CODE BEGIN StartBootOcIgla */
  /* Infinite loop */

	  osDelay(3000);

	  htim1.Init.CounterMode = TIM_COUNTERMODE_CENTERALIGNED1;
	  HAL_TIM_Base_Init(&htim1);

	  HAL_TIM_Base_Start_IT(&htim1);
	  HAL_TIM_PWM_Start(&htim1, TIM_CHANNEL_1);
	  HAL_TIM_PWM_Start(&htim1, TIM_CHANNEL_2);

  for(;;)
  {
    osDelay(1);
  }
  /* USER CODE END StartBootOcIgla */
}

void StartBuzzerCoolerLed_5Sec(void *argument)
{
  for(;;)
  {
    osDelay(1);
  }
}

void StartADC_TEMP_V16_RAW(void *argument)
{
  for(;;)
  {
    osDelay(1);
  }
}

void StartUART_I2C(void *argument)
{
  for(;;)
  {
    osDelay(1);
  }
}

/************************ (C) COPYRIGHT STMicroelectronics *****END OF FILE****/
